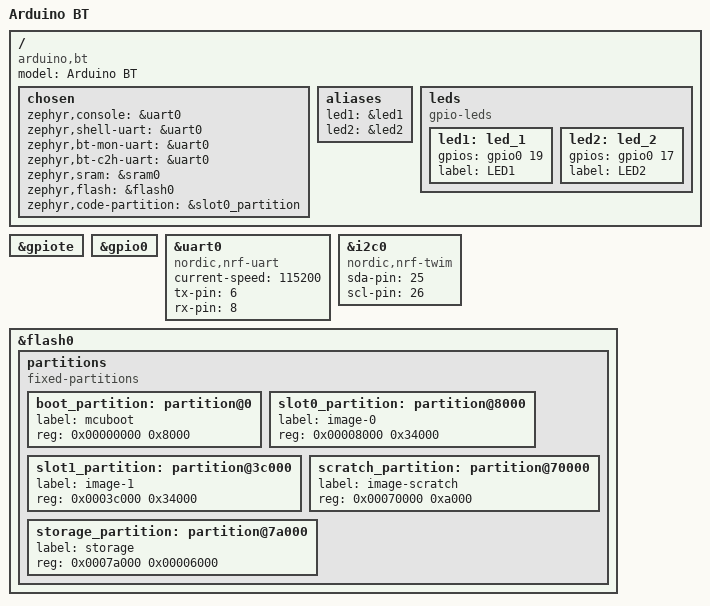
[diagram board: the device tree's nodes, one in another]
/*
 * Copyright (c) 2017 Linaro Limited
 *
 * SPDX-License-Identifier: Apache-2.0
 */

/dts-v1/;
#include <nordic/nrf52832_qfaa.dtsi>

/ {
	model = "Arduino BT";
	compatible = "arduino,bt", "nordic,nrf52832-qfaa",
		     "nordic,nrf52832";

	chosen {
		zephyr,console = &uart0;
		zephyr,shell-uart = &uart0;
		zephyr,bt-mon-uart = &uart0;
		zephyr,bt-c2h-uart = &uart0;
		zephyr,sram = &sram0;
		zephyr,flash = &flash0;
		zephyr,code-partition = &slot0_partition;
	};

	/* These aliases are provided for compatibility with samples */
	aliases {
		led1 = &led1;
		led2 = &led2;
	};

	leds {
		compatible = "gpio-leds";
		led1: led_1 {
			gpios = <&gpio0 19 0>;
			label = "LED1";
		};
		led2: led_2 {
			gpios = <&gpio0 17 0>;
			label = "LED2";
		};
	};
};

&gpiote {
	status = "okay";
};

&gpio0 {
	status = "okay";
};

&uart0 {
	compatible = "nordic,nrf-uart";
	current-speed = <115200>;
	status = "okay";
	tx-pin = <6>;
	rx-pin = <8>;
};

&i2c0 {
	compatible = "nordic,nrf-twim";
	status = "okay";
	sda-pin = <25>;
	scl-pin = <26>;
};

&flash0 {
	/*
	 * For more information, see:
	 * http://docs.zephyrproject.org/latest/guides/dts/index.html#flash-partitions
	 */
	partitions {
		compatible = "fixed-partitions";
		#address-cells = <1>;
		#size-cells = <1>;

		boot_partition: partition@0 {
			label = "mcuboot";
			reg = <0x00000000 0x8000>;
		};
		slot0_partition: partition@8000 {
			label = "image-0";
			reg = <0x00008000 0x34000>;
		};
		slot1_partition: partition@3c000 {
			label = "image-1";
			reg = <0x0003c000 0x34000>;
		};
		scratch_partition: partition@70000 {
			label = "image-scratch";
			reg = <0x00070000 0xa000>;
		};

		/*
		 * The flash starting at 0x0007a000 and ending at
		 * 0x0007ffff (sectors 122-127) is reserved for use
		 * by the application. If enabled, partition for FCB/NFFS
		 * will be created in this area.
		 */
		storage_partition: partition@7a000 {
			label = "storage";
			reg = <0x0007a000 0x00006000>;
		};
	};
};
